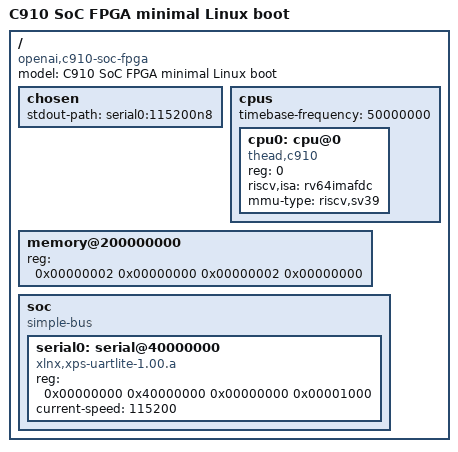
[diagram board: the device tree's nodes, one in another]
/dts-v1/;

/ {
	#address-cells = <2>;
	#size-cells = <2>;
	compatible = "openai,c910-soc-fpga", "thead,c910";
	model = "C910 SoC FPGA minimal Linux boot";

	chosen {
		stdout-path = "serial0:115200n8";
	};

	cpus {
		#address-cells = <1>;
		#size-cells = <0>;
		timebase-frequency = <50000000>;

		cpu0: cpu@0 {
			device_type = "cpu";
			reg = <0>;
			status = "okay";
			compatible = "thead,c910", "riscv";
			riscv,isa = "rv64imafdc";
			mmu-type = "riscv,sv39";
		};
	};

	memory@200000000 {
		device_type = "memory";
		reg = <0x00000002 0x00000000 0x00000002 0x00000000>;
	};

	soc {
		#address-cells = <2>;
		#size-cells = <2>;
		compatible = "simple-bus";
		ranges;

		serial0: serial@40000000 {
			compatible = "xlnx,xps-uartlite-1.00.a";
			reg = <0x00000000 0x40000000 0x00000000 0x00001000>;
			current-speed = <115200>;
			status = "okay";
		};
	};
};
